VERSION ""

NS_ :

BS_:

BU_: DBG DRIVER IO MOTOR SENSOR GEO

BO_ 100 DRIVER_HEARTBEAT: 1 DRIVER
 SG_ DRIVER_HEARTBEAT_cmd: 0|8@1+ (1,0) [0|0] "" GEO,MOTOR,SENSOR

BO_ 101 GEO_HEARTBEAT: 1 GEO
 SG_ GEO_HEARTBEAT_cmd: 0|8@1+ (1,0) [0|0] "" DRIVER,MOTOR,SENSOR

BO_ 102 MOTOR_HEARTBEAT: 1 MOTOR
 SG_ MOTOR_HEARTBEAT_cmd: 0|8@1+ (1,0) [0|0] "" DRIVER,GEO,SENSOR

BO_ 103 SENSOR_HEARTBEAT: 1 SENSOR
 SG_ SENSOR_HEARTBEAT_cmd: 0|8@1+ (1,0) [0|0] "" DRIVER,GEO,MOTOR

BO_ 200 MOTOR_STEERING: 1 DRIVER
 SG_ MOTOR_STEERING_direction: 0|8@1- (1,0) [-2|2] "" MOTOR

BO_ 210 DRIVER_COORDINATES: 8 DRIVER
 SG_ DRIVER_COORDINATES_latitude: 0|32@1- (0.000001,-90) [-90|90] "degrees" GEO
 SG_ DRIVER_COORDINATES_longitude: 32|32@1- (0.000001,-180) [-180|180] "degrees" GEO

BO_ 220 MOTOR_SPEED: 1 DRIVER
 SG_ MOTOR_SPEED_processed: 0|8@1- (1,0) [-3|3] "" MOTOR

BO_ 300 GEO_DEGREE: 8 GEO
 SG_ GEO_DEGREE_current: 0|32@1+ (0.000001,0) [0|360] "degrees" DRIVER
 SG_ GEO_DEGREE_required: 32|32@1+ (0.000001,0) [0|360] "degrees" DRIVER

BO_ 310 GEO_DESTINATION_REACHED: 1 GEO
 SG_ GEO_DESTINATION_REACHED_cmd: 0|8@1+ (1,0) [0|0] "" DRIVER

BO_ 400 MOTOR_SPEED_FEEDBACK: 4 MOTOR
 SG_ MOTOR_SPEED_current: 0|32@1+ (0.1,0) [0|60] "kph" DRIVER

BO_ 500 SENSOR_BT_COORDINATES: 8 SENSOR
 SG_ SENSOR_BT_COORDINATES_latitude: 0|32@1- (0.000001,-90) [-90|90] "degrees" GEO
 SG_ SENSOR_BT_COORDINATES_longitude: 32|32@1- (0.000001,-180) [-180|180] "degrees" GEO

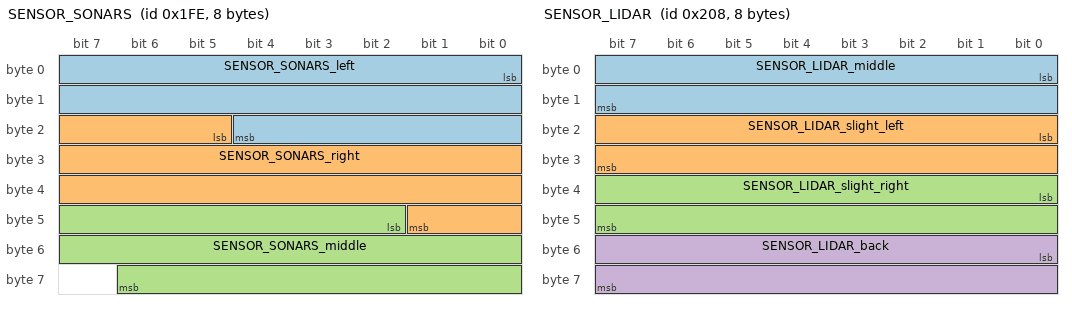
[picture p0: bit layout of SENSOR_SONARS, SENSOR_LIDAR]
BO_ 510 SENSOR_SONARS: 8 SENSOR
 SG_ SENSOR_SONARS_left: 0|21@1+ (0.001,0) [0|0] "cm" DRIVER
 SG_ SENSOR_SONARS_right: 21|21@1+ (0.001,0) [0|0] "cm" DRIVER
 SG_ SENSOR_SONARS_middle: 42|21@1+ (0.001,0) [0|0] "cm" DRIVER

BO_ 520 SENSOR_LIDAR: 8 SENSOR
 SG_ SENSOR_LIDAR_middle: 0|16@1+ (1,0) [0|0] "cm" DRIVER
 SG_ SENSOR_LIDAR_slight_left: 16|16@1+ (1,0) [0|0] "cm" DRIVER
 SG_ SENSOR_LIDAR_slight_right: 32|16@1+ (1,0) [0|0] "cm" DRIVER
 SG_ SENSOR_LIDAR_back: 48|16@1+ (1,0) [0|0] "cm" DRIVER

BO_ 530 MOTOR_KEY: 1 SENSOR
 SG_ MOTOR_KEY_val: 0|8@1+ (1,0) [0|0] "" DRIVER

BO_ 900 GEO_CURRENT_COORDINATES: 8 GEO
 SG_ GEO_CURRENT_COORDINATES_latitude: 0|32@1- (0.000001,-90) [-90|90] "degrees" DBG
 SG_ GEO_CURRENT_COORDINATES_longitude: 32|32@1- (0.000001,-180) [-180|180] "degrees" DBG

BO_ 901 GEO_DISTANCE_FROM_DESTINATION: 4 GEO
 SG_ GEO_distance_from_destination: 0|32@1+ (0.001,0) [0|0] "meters" DBG

BO_ 902 MOTOR_INFO_DBG: 4 MOTOR
 SG_ MOTOR_INFO_DBG_rps: 0|16@1+ (1,0) [0|0] "" DBG
 SG_ MOTOR_INFO_DBG_pwm: 16|16@1+ (0.001,0) [0|0] "" DBG

BO_ 903 LIPO_BATTERY_VOLTAGE_DBG: 4 MOTOR
 SG_ LIPO_BATTERY_VOLTAGE_val: 0|32@1+ (0.01,0) [0|0] "volts" DBG

BO_ 904 CURRENT_CHECKPOINT_DBG: 1 GEO
 SG_ CURRENT_CHECKPOINT_val: 0|8@1+ (1,0) [0|0] "" DBG

CM_ "--BU (Network Node) Information--";
CM_ BU_ DRIVER "The driver controller of the car";
CM_ BU_ GEO "The geo controller of the car";
CM_ BU_ MOTOR "The motor controller of the car";
CM_ BU_ SENSOR "The sensor controller of the car";

CM_ "--BO (Message) Information--";
CM_ BO_ 100 "Driver Sync message used to synchronize the controllers";
CM_ BO_ 101 "Geo Sync message used to synchronize the controllers";
CM_ BO_ 102 "Motor Sync message used to synchronize the controllers";
CM_ BO_ 103 "Sensor Sync message used to synchronize the controllers";

CM_ BO_ 200 "Steering direction values sent by Driver Node to Motor Node";
CM_ BO_ 210 "Driver Destination coordinates sent by Driver Node";
CM_ BO_ 220 "Required motor speed computed from Driver Node to Motor Node";

CM_ BO_ 300 "Current and computer/required degree values sent by Geo Node";
CM_ BO_ 310 "Indicator signal to check if the RC car has reached the destination";

CM_ BO_ 400 "Current motor info (rps and kph) sent as feedback to the Driver Node";

CM_ BO_ 500 "Coordinate BT values (destination coordinates) sent by Sensor Node";
CM_ BO_ 510 "LIDAR - Distance from obstacle detected in each sector";
CM_ BO_ 520 "Ultrasonic Sensor - Distance from obstacle detected by each sensor";
CM_ BO_ 530 "Start/Stop signal from the Bluetooth app";

CM_ BO_ 900 "Destination coordinates for BUSMASTER debugging";
CM_ BO_ 901 "Distance from destination";
CM_ BO_ 902 "Supplied PWM value to the motor and its RPM";
CM_ BO_ 903 "LIPO Battery Voltage";
CM_ BO_ 904 "Current checkpoint of the car";

CM_ "--SG (Signal) Information for Heartbeats--";
CM_ SG_ 100 DRIVER_HEARTBEAT_cmd "Heartbeat command from the driver node";
CM_ SG_ 101 GEO_HEARTBEAT_cmd "Heartbeat command from the geological node";
CM_ SG_ 102 MOTOR_HEARTBEAT_cmd "Heartbeat command from the motor node";
CM_ SG_ 103 SENSOR_HEARTBEAT_cmd "Heartbeat command from the sensor node";

CM_ "--SG (Signal) Information for DRIVER Node--";
CM_ SG_ 200 DRIVER_STEERING_direction "Calculated Driver Steering values (-2,2) for Motor";
CM_ SG_ 210 DRIVER_COORDINATES_latitude "Destination Latitude coordinate";
CM_ SG_ 210 DRIVER_COORDINATES_longitude "Destination Longitude coordinate";
CM_ SG_ 220 MOTOR_SPEED "Calculated Driver speed values (-3,3) for Motor";

CM_ "--SG (Signal) Information for GEO Node--";
CM_ SG_ 300 GEO_DEGREE_current "Current Geo Degree relative to true north";
CM_ SG_ 300 GEO_DEGREE_required "Calculated Geo Degree computed by Haversine Formula";
CM_ SG_ 310 GEO_DESTINATION_REACHED "Indicator signal to check if the RC car has reached the destination";

CM_ "--SG (Signal) Information for MOTOR Node--";
CM_ SG_ 400 MOTOR_SPEED_FEEDBACK "Feedback speed (kph) sent by Motor Node";

CM_ "--SG (Signal) Information for SENSOR Node--";
CM_ SG_ 500 SENSOR_BT_COORDINATES_latitude "Destination Latitude received over Bluetooth";
CM_ SG_ 500 SENSOR_BT_COORDINATES_longitude "Destination Longitude received over Bluetooth";
CM_ SG_ 510 SENSOR_SONARS_left "Ultrasonic Sensor attached to the left side";
CM_ SG_ 510 SENSOR_SONARS_right "Ultrasonic Sensor attached to the right side";
CM_ SG_ 510 SENSOR_SONARS_middle "Ultrasonic Sensor attached to the middle";
CM_ SG_ 510 SENSOR_SONARS_back_left "Ultrasonic Sensor attached to the back left side";
CM_ SG_ 510 SENSOR_SONARS_back_right "Ultrasonic Sensor attached to the back right side";
CM_ SG_ 520 SENSOR_LIDAR_middle "Lidar sensing the middle sector (-15 to 15 degrees)";
CM_ SG_ 520 SENSOR_LIDAR_slight_left "Lidar sensing the slight left sector (-45 to -15 degrees)";
CM_ SG_ 520 SENSOR_LIDAR_slight_right "Lidar sensing the slight right sector (15 to 45 degrees)";
CM_ SG_ 520 SENSOR_LIDAR_back "Lidar sensing the back of the car (165 to 195 degrees)";
CM_ SG_ 530 MOTOR_KEY_val "1 -> Start the motor from the app, 0 -> Stop";

CM_ SG_ 900 GEO_CURRENT_COORDINATES_latitude "Current Latitude";
CM_ SG_ 900 GEO_CURRENT_COORDINATES_longitude "Current Longitude";
CM_ SG_ 901 GEO_distance_from_destination "Distance from destination";
CM_ SG_ 902 MOTOR_INFO_DBG_rps "Current RPS value of the motor";
CM_ SG_ 902 MOTOR_INFO_DBG_pwm "Supplied motor PWM value";
CM_ SG_ 903 LIPO_BATTERY_VOLTAGE_val "LIPO Battery Voltage";
CM_ SG_ 904 CURRENT_CHECKPOINT_val "Current checkpoint of the car";

BA_DEF_ "BusType" STRING ;
BA_DEF_ BO_ "GenMsgCycleTime" INT 0 0;
BA_DEF_ SG_ "FieldType" STRING ;

BA_DEF_DEF_ "BusType" "CAN";
BA_DEF_DEF_ "FieldType" "";
BA_DEF_DEF_ "GenMsgCycleTime" 0;

BA_ "GenMsgCycleTime" BO_ 100 1000;
BA_ "GenMsgCycleTime" BO_ 200 50;
BA_ "FieldType" SG_ 100 DRIVER_HEARTBEAT_cmd "DRIVER_HEARTBEAT_cmd";
BA_ "FieldType" SG_ 102 GEO_HEARTBEAT_cmd "GEO_HEARTBEAT_cmd";
BA_ "FieldType" SG_ 103 MOTOR_HEARTBEAT_cmd "MOTOR_HEARTBEAT_cmd";
BA_ "FieldType" SG_ 104 SENSOR_HEARTBEAT_cmd "SENSOR_HEARTBEAT_cmd";

BA_ "FieldType" SG_ 200 MOTOR_STEERING "MOTOR_STEERING";
BA_ "FieldType" SG_ 230 MOTOR_SPEED_val "MOTOR_SPEED_val";
BA_ "FieldType" SG_ 310 GEO_DESTINATION_REACHED_cmd "GEO_DESTINATION_REACHED_cmd";

VAL_ 100 DRIVER_HEARTBEAT_cmd 2 "DRIVER_HEARTBEAT_cmd_REBOOT" 1 "DRIVER_HEARTBEAT_cmd_SYNC" 0 "DRIVER_HEARTBEAT_cmd_NOOP" ;
VAL_ 101 GEO_HEARTBEAT_cmd 2 "GEO_HEARTBEAT_cmd_REBOOT" 1 "GEO_HEARTBEAT_cmd_SYNC" 0 "GEO_HEARTBEAT_cmd_NOOP";
VAL_ 102 MOTOR_HEARTBEAT_cmd 20 "MOTOR_HEARTBEAT_cmd_REBOOT" 10 "MOTOR_HEARTBEAT_cmd_SYNC" 0 "MOTOR_HEARTBEAT_cmd_NOOP" ;
VAL_ 103 SENSOR_HEARTBEAT_cmd 200 "SENSOR_HEARTBEAT_cmd_REBOOT" 100 "SENSOR_HEARTBEAT_cmd_SYNC" 0 "SENSOR_HEARTBEAT_cmd_NOOP" ;

VAL_ 200 MOTOR_STEERING_direction -2 "MOTOR_STEERING_hard_left" -1 "MOTOR_STEERING_slight_left" 0 "MOTOR_STEERING_straight" 1 "MOTOR_STEERING_slight_right" 2 "MOTOR_STEERING_hard_right";
VAL_ 220 MOTOR_SPEED_processed -3 "MOTOR_SPEED_reverse_fast" -2 "MOTOR_SPEED_reverse_medium" -1 "MOTOR_SPEED_reverse_slow" 0 "MOTOR_SPEED_neutral" 1 "MOTOR_SPEED_forward_slow" 2 "MOTOR_SPEED_forward_medium" 3 "MOTOR_SPEED_forward_fast";
VAL_ 310 GEO_DESTINATION_REACHED_cmd 1 "GEO_DESTINATION_REACHED_cmd_REACHED" 0 "GEO_DESTINATION_REACHED_cmd_NOT_REACHED";
